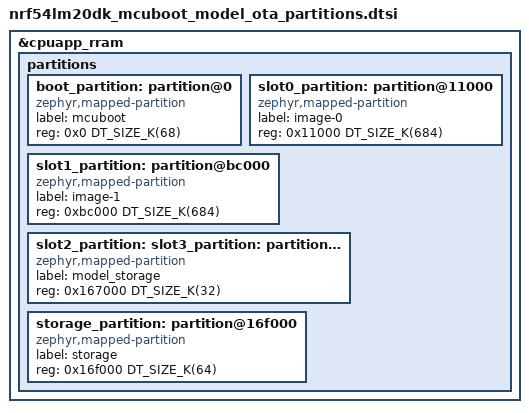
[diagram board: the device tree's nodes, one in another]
/*
 * Copyright (c) 2026 Nordic Semiconductor ASA
 *
 * SPDX-License-Identifier: LicenseRef-Nordic-5-Clause
 *
 * Flash partition map for regression model OTA on nRF54LM20 DK.
 * Single-slot model layout: one physical region aliased as consecutive MCUboot slot pair
 * (image 1 = regression model). Image 0 keeps dual-slot swap.
 */

/delete-node/ &boot_partition;
/delete-node/ &slot0_partition;
/delete-node/ &slot1_partition;
/delete-node/ &storage_partition;

&cpuapp_rram {
	partitions {
		boot_partition: partition@0 {
			compatible = "zephyr,mapped-partition";
			label = "mcuboot";
			reg = <0x0 DT_SIZE_K(68)>;
		};

		/* Image 0: firmware - equal sizes required for swap-using-move */
		slot0_partition: partition@11000 {
			compatible = "zephyr,mapped-partition";
			label = "image-0";
			reg = <0x11000 DT_SIZE_K(684)>;
		};
		slot1_partition: partition@bc000 {
			compatible = "zephyr,mapped-partition";
			label = "image-1";
			reg = <0xbc000 DT_SIZE_K(684)>;
		};

		/* Image 1: regression model - slot2/slot3 alias the same region */
		slot2_partition: slot3_partition: model_storage: partition@167000 {
			compatible = "zephyr,mapped-partition";
			label = "model_storage";
			reg = <0x167000 DT_SIZE_K(32)>;
		};

		storage_partition: partition@16f000 {
			compatible = "zephyr,mapped-partition";
			label = "storage";
			reg = <0x16f000 DT_SIZE_K(64)>;
		};
	};
};
